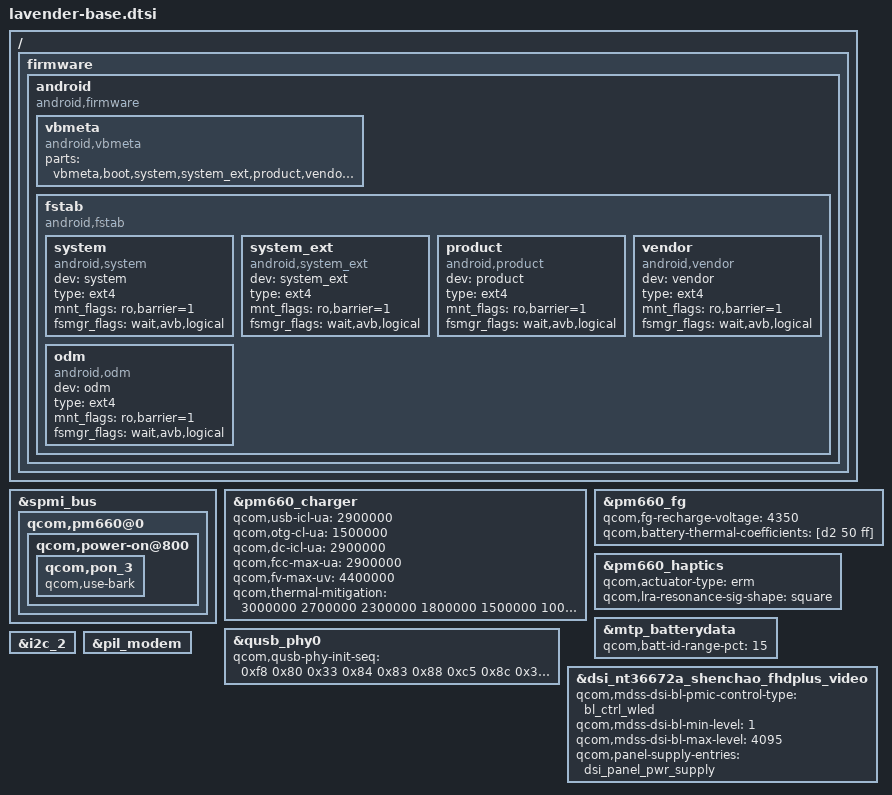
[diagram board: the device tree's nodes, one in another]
// SPDX-License-Identifier: GPL-2.0-only

#include "sdm660-camera-sensor-mtp_f7a.dtsi"
#include "sdm660-i2c_f7a.dtsi"

/* msm-pm660.dtsi lavender specific diff */
/ {
	firmware {
		android {
			compatible = "android,firmware";

			vbmeta {
				compatible = "android,vbmeta";
				parts = "vbmeta,boot,system,system_ext,product,vendor,odm,dtbo,recovery";
		};
		
		fstab {
			compatible = "android,fstab";
			system {
				compatible = "android,system";
				dev = "system";
				type = "ext4";
				mnt_flags = "ro,barrier=1";
				fsmgr_flags = "wait,avb,logical";
				status = "ok";
			};
			system_ext {
				compatible = "android,system_ext";
				dev = "system_ext";
				type = "ext4";
				mnt_flags = "ro,barrier=1";
				fsmgr_flags = "wait,avb,logical";
				status = "ok";
			};
			product {
				compatible = "android,product";
				dev = "product";
				type = "ext4";
				mnt_flags = "ro,barrier=1";
				fsmgr_flags = "wait,avb,logical";
				status = "ok";
			};
			vendor {
				compatible = "android,vendor";
				dev = "vendor";
				type = "ext4";
				mnt_flags = "ro,barrier=1";
				fsmgr_flags = "wait,avb,logical";
				status = "ok";
			};
			odm {
				compatible = "android,odm";
				dev = "odm";
				type = "ext4";
				mnt_flags = "ro,barrier=1";
				fsmgr_flags = "wait,avb,logical";
				status = "ok";
				};
			};
		};
	};
};

&spmi_bus {
	qcom,pm660@0 {
		qcom,power-on@800 {
			qcom,pon_3 {
				qcom,use-bark;
			};
		};
	};
};

&pm660_charger {
	qcom,usb-icl-ua = <2900000>;
	qcom,otg-cl-ua = <1500000>;
	qcom,dc-icl-ua = <2900000>;
	qcom,fcc-max-ua = <2900000>;
	qcom,fv-max-uv = <4400000>;
	qcom,thermal-mitigation = <3000000 2700000 2300000 1800000 1500000 1000000 500000>;
};

&pm660_fg {
	qcom,fg-recharge-voltage = <4350>;
	qcom,battery-thermal-coefficients = [d2 50 ff];
};

&pm660_haptics {
	qcom,actuator-type = "erm";
	qcom,lra-resonance-sig-shape = "square";
};

/* sdm660-common.dtsi lavender specific diff */
&qusb_phy0 {
	qcom,qusb-phy-init-seq = <
		0xf8 0x80
		0x33 0x84
		0x83 0x88
		0xc5 0x8c
		0x30 0x08
		0x79 0x0c
		0x21 0x10
		0x14 0x9c
		0x9f 0x1c
		0x00 0x18
	>;
};

/* sdm660-mtp.dtsi lavender specific diff */
&mtp_batterydata {
	qcom,batt-id-range-pct = <15>;
	#include "fg-gen3-batterydata-m6100atl-4000mah.dtsi"
	#include "fg-gen3-batterydata-m6100sun-4000mah.dtsi"
	#include "fg-gen3-batterydata-m6100cos-4000mah.dtsi"
	#include "fg-gen3-batterydata-m6100default-4000mah.dtsi"
};

&dsi_nt36672a_shenchao_fhdplus_video {
	qcom,mdss-dsi-bl-pmic-control-type = "bl_ctrl_wled";
	qcom,mdss-dsi-bl-min-level = <1>;
	qcom,mdss-dsi-bl-max-level = <4095>;
	qcom,panel-supply-entries = <&dsi_panel_pwr_supply>;
};

&i2c_2 {
	/delete-property/ status;
	/delete-node/ smb1351-charger@1d;
};

/* sdm660.dtsi lavender specific diff */
&pil_modem {
	/delete-property/ qcom,complete-ramdump;
};
